# RL6678_IP_SVD register map
Vendor: Realtek
Registers are 32-bit, read-write, reset 0x0 unless marked. A register's access mark holds for its fields unless they carry their own. Offsets are from the block's base; [hi:lo] are bit positions; {n}, {i} and the like mark numbered series.

## MIPI_DSI_REG
Base 0x400EA000
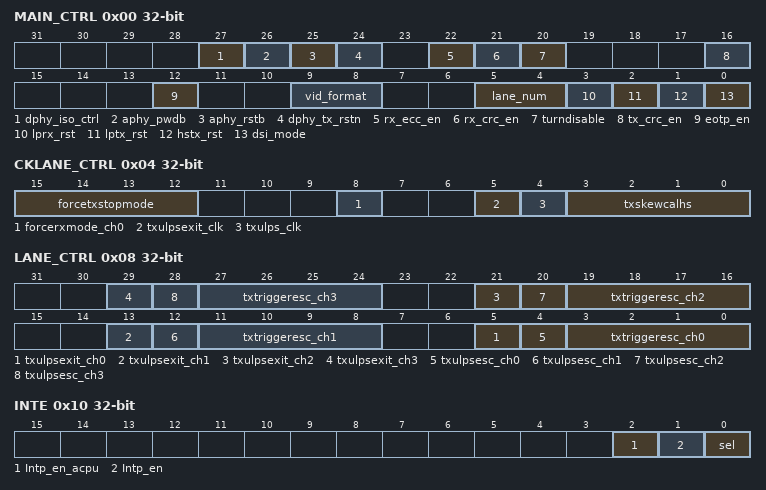
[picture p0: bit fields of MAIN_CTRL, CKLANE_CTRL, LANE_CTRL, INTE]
0x00 MAIN_CTRL
  [27] dphy_iso_ctrl — DPHY isolation function control 1: isolation mode 0: normal mode Related to DPHY port: BY_PASS_ON_MIPI
  [26] aphy_pwdb — APHY core power down signal for isolation
  [25] aphy_rstb — APHY reset signal
  [24] dphy_tx_rstn — DPHY external reset
  [22] rx_ecc_en — RX ECC check and correction enable
  [21] rx_crc_en — RX CRC check enable
  [20] turndisable — Disable Bus Turn Around (BTA) function.
  [16] tx_crc_en — TX CRC calculation enable
  [12] eotp_en — EOT packet enable
  [9:8] vid_format — Video stream data format 2'b00: 24bpp (8, 8, 8 RGB) 2'b01: 16bpp (5, 6, 5 RGB) 2'b10: 18bpp (6, 6, 6 RGB) packed 2'b11: 18bpp (6, 6, 6, RGB) loosely packed
  [5:4] lane_num — Lane number setting 2'b00: 1-lane 2'b01: 2-lane 2'b10: 3-lane 2'b11: 4-lane
  [3] lprx_rst — Async SW reset for LPRX function, set 1'b1 to reset LPRX function.
  [2] lptx_rst — Async SW reset for LPTX function, set 1'b1 to reset LPTX function.
  [1] hstx_rst — Async SW reset for HSTX function, set 1'b1 to reset HSTX function.
  [0] dsi_mode — DSI mode selection 0: command mode 1: video mode (shall be set after timing contrl register)
0x04 CKLANE_CTRL
  [15:12] forcetxstopmode — Force TX STOP
  [8] forcerxmode_ch0 — Force LPRX mode
  [5] txulpsexit_clk — Clock ULPS mode exit
  [4] txulps_clk — Clock ULPS mode enable
  [3:0] txskewcalhs — Skew Calibration
0x08 LANE_CTRL
  [8n+5] txulpsexit_ch{n} (n=0..3), [8n+4] txulpsesc_ch{n} (n=0..3), [8n+3:8n] txtriggeresc_ch{n} (n=0..3)
0x10 INTE
  [2] Intp_en_acpu — Set 1'b1 to enable DSI ACPU interrupt
  [1] Intp_en — Set 1'b1 to enable DSI SCPU interrupt
  [0] sel — Select which CPU to interrupt 0: SCPU 1: ACPU
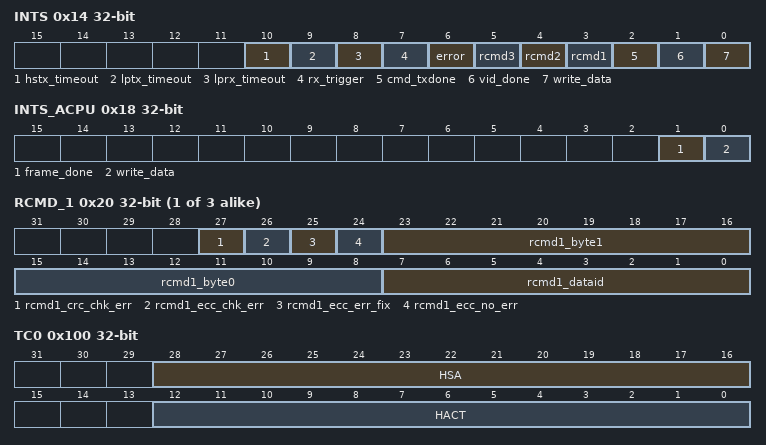
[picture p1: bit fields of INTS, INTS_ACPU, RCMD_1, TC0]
0x14 INTS access per field
  [10] hstx_timeout rw — HS Tx mode, timeout
  [9] lptx_timeout rw — LP Tx mode, timeout
  [8] lprx_timeout rw — LP Rx mode, timeout
  [7] rx_trigger rw — Received Rx trigger signal in DPHY_STATUS1
  [6] error rw — Error report in register DPHY_ERR
  [5] rcmd3 rw — Receive command mode response at RCMD3
  [4] rcmd2 rw — Receive command mode response at RCMD2
  [3] rcmd1 rw — Receive command mode response at RCMD1
  [2] cmd_txdone rw — Command mode Tx done
  [1] vid_done rw — Video mode frame Tx done
  [0] write_data wo
0x18 INTS_ACPU access per field
  [1] frame_done rw — Video mode frame done
  [0] write_data wo
{0x1C+4i} RCMD_{i} ro (i=1..3)
  [27] rcmd{i}_crc_chk_err — RCMD CRC check error
  [26] rcmd{i}_ecc_chk_err — RCMD ECC check error can't be fixed.
  [25] rcmd{i}_ecc_err_fix — RCMD ECC check error but fixed
  [24] rcmd{i}_ecc_no_err — RCMD ECC check error free
  [23:16] rcmd{i}_byte1 — Short command/long command header
  [15:8] rcmd{i}_byte0 — Short command/long command header
  [7:0] rcmd{i}_dataid — Short command/long command header
0x100 TC0
  [28:16] HSA — Set Hsync pulse width in bytes
  [12:0] HACT — Set video active width in bytes
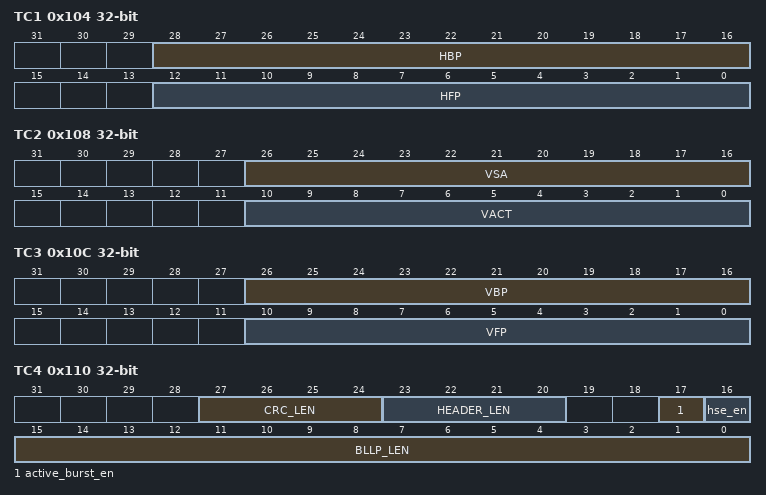
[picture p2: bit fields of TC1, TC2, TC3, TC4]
0x104 TC1
  [28:16] HBP — Set Horizontal Back Porch in bytes
  [12:0] HFP — Set Horizontal Front Porch in bytes
0x108 TC2
  [26:16] VSA — Set Vsync pulse width in Line
  [10:0] VACT — Set video active scan line numbers
0x10C TC3
  [26:16] VBP — Set Vertical Back Porch in Line
  [10:0] VFP — Set Vertical Front Porch in Line
0x110 TC4
  [27:24] CRC_LEN — Set HS mode CRC length in bytes
  [23:20] HEADER_LEN — Set HS mode Header length in bytes
  [17] active_burst_en — Send active data in burst mode (send EOTP in active lines)
  [16] hse_en — Enable register for Hsync end event packet
  [15:0] BLLP_LEN — Set clock request timing in byteclk cycles
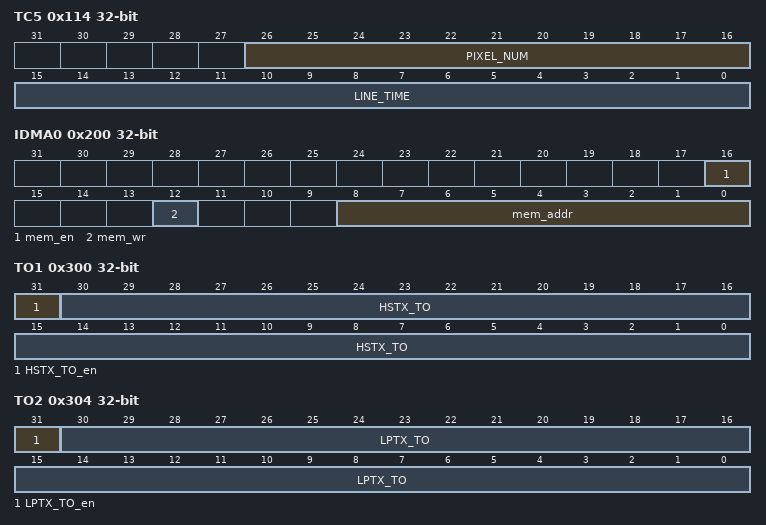
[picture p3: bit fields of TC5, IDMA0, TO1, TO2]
0x114 TC5
  [26:16] PIXEL_NUM — Set pixel numbers in pixel for VO PIF
  [15:0] LINE_TIME — Set HSTX line time in byteclk cycles
0x200 IDMA0
  [16] mem_en — In-direct memory access enable
  [12] mem_wr — 0: memory write 1: memory read
  [8:0] mem_addr — In-direct memory access
0x204 IDMA1
  [31:0] mem_d0 — Memory data bit[31:0]
0x208 IDMA2
  [31:0] mem_d1 — Memory data bit[63:32]
0x300 TO1
  [31] HSTX_TO_en — HSTX timout enable
  [30:0] HSTX_TO — HSTX timeout
0x304 TO2
  [31] LPTX_TO_en — LPTX timout enable
  [30:0] LPTX_TO — LPTX timeout
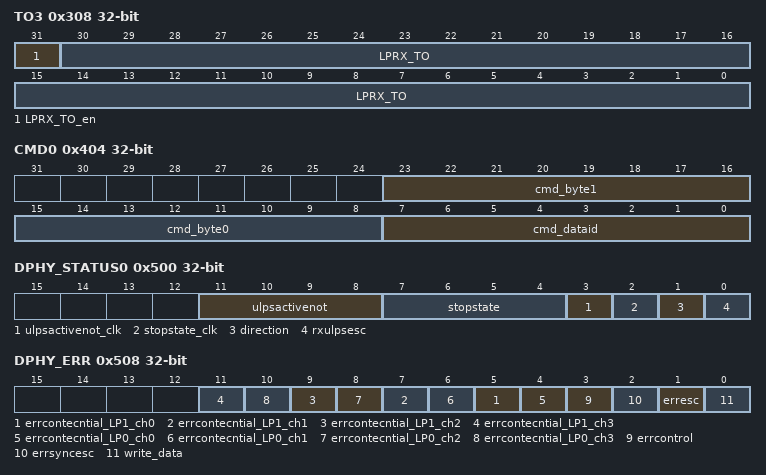
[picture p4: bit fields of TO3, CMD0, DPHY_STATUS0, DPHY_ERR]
0x308 TO3
  [31] LPRX_TO_en — LPRX timout enable
  [30:0] LPRX_TO — LPRX timeout
0x30C TO4
  [3:0] FIFO_RE_DLY — After FIFO_RE_DLY clock cycles delay, start to read FIFO to send HS data
0x400 CMD_GO
  [0] cmd_go — Set 1'b1 to start command transmission sequence
0x404 CMD0
  [23:16] cmd_byte1 — Short command/long command header direct write
  [15:8] cmd_byte0 — Short command/long command header direct write
  [7:0] cmd_dataid — Short command/long command header direct write
0x500 DPHY_STATUS0 ro
  [11:8] ulpsactivenot — Data lane ULPS mode indicator
  [7:4] stopstate — Data lane Stop State indicator
  [3] ulpsactivenot_clk — CLK lane ULPS mode indicator
  [2] stopstate_clk — CLK lane Stop State indicator
  [1] direction — Low Power Lane direction
  [0] rxulpsesc — RX ULPS mode indicator
0x504 DPHY_STATUS1 ro
  [3:0] rxtriggeresc — Escape mode trigger
0x508 DPHY_ERR access per field
  [2n+5] errcontecntial_LP1_ch{n} rw (n=0..3), [2n+4] errcontecntial_LP0_ch{n} rw (n=0..3), [3] errcontrol rw, [2] errsyncesc rw, [1] erresc rw, [0] write_data wo
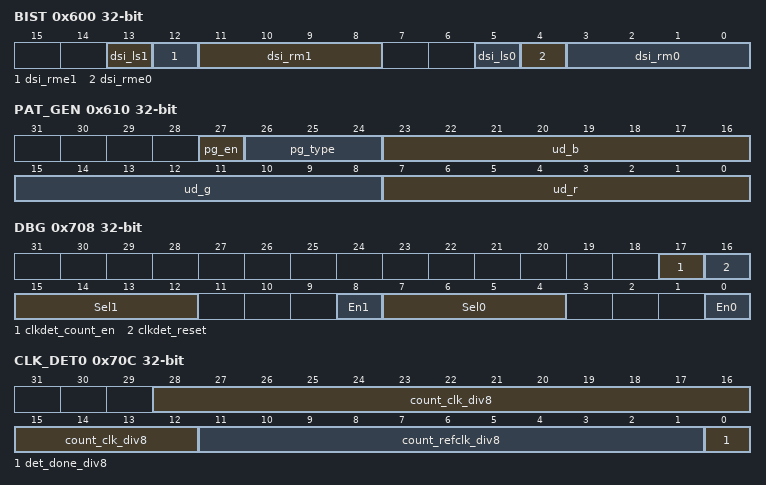
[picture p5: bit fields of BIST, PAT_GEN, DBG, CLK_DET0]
0x600 BIST
  [13] dsi_ls1 — LS control 1
  [12] dsi_rme1 — REM1
  [11:8] dsi_rm1 — RM1
  [5] dsi_ls0 — LS control 0
  [4] dsi_rme0 — REM0
  [3:0] dsi_rm0 — RM0
0x610 PAT_GEN
  [27] pg_en — Pattern generator enable
  [26:24] pg_type — 3'h0: color bar 3'h1: black 3'h2: white 3'h3: red 3'h4: blue 3'h5: yellow 3'h6: magenta 3'h7: user defined (ud_r, ud_g, ud_b)
  [23:16] ud_b — User-defined blue color space
  [15:8] ud_g — User-defined green color space
  [7:0] ud_r — User-defined red color space
0x700 DUMMY0
  [31:0] dummy_reg0 — Dummy register
0x704 DUMMY1
  [31:0] dummy_reg1 — Dummy register
0x708 DBG
  [17] clkdet_count_en — 1: start clock frequency detection
  [16] clkdet_reset — 0: reset crt_pll_div clk det function
  [15:12] Sel1 — Mux select for di_dbg_out1
  [8] En1 — Output enable for di_dbg_out1
  [7:4] Sel0 — Mux select for di_dbg_out0
  [0] En0 — Output enable for di_dbg_out0
0x70C CLK_DET0 ro
  [28:12] count_clk_div8 — Counter output
  [11:1] count_refclk_div8 — Counter output of ref clock
  [0] det_done_div8 — Clock detect done
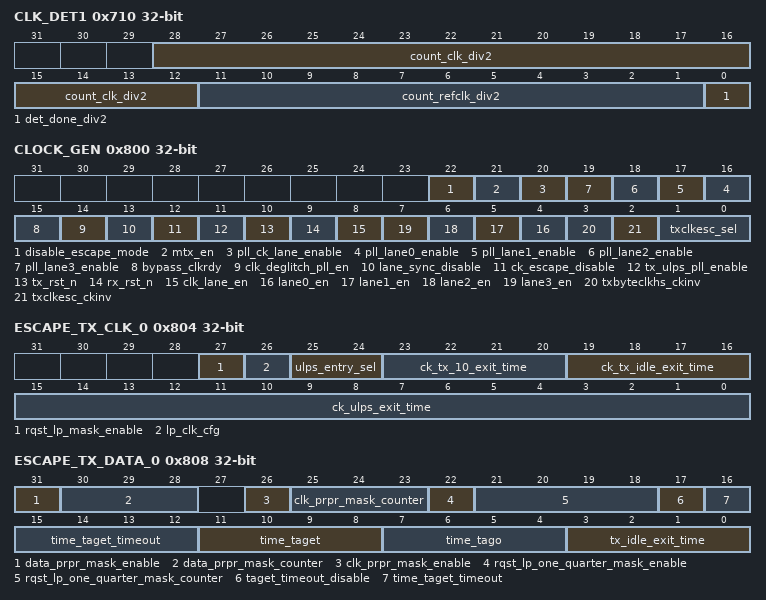
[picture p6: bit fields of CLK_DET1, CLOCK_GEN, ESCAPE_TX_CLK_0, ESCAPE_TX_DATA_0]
0x710 CLK_DET1 ro
  [28:12] count_clk_div2 — Counter output
  [11:1] count_refclk_div2 — Counter output of ref clock
  [0] det_done_div2 — Clock detect done
0x714 DBG_ST0 ro
  [31:0] dbg_pif — Debug status
0x718 DBG_ST1 ro
  [31:0] dbg_timegen — Debug status
0x71C DBG_ST2 ro
  [31:0] dbg_pktgen — Debug status
0x720 DBG_ST3 ro
  [31:0] dbg_ch_ctrl — Debug status
0x724 DBG_ST4 ro
  [31:0] dbg_cmd — Debug status
0x800 CLOCK_GEN
  [22] disable_escape_mode
  [21] mtx_en — Register for MTX_EN
  [20] pll_ck_lane_enable — Enable ulpsactivenot_ck_lane to control PLL enable
  [n+16] pll_lane{n}_enable (n=0..3) — Enable ulpsactivenot_ch{n} to control PLL enable
  [15] bypass_clkrdy — Clock gating bypass clkrdy
  [14] clk_deglitch_pll_en — PLL_EN clock deglitch 1'B1: Deglitch enable 1'B0: deglitch disable
  [13] lane_sync_disable — 4 lane sync disable
  [12] ck_escape_disable — Disable Tx Ctrl FSM TX_CK_RQST wait ck_escape_entry
  [11] tx_ulps_pll_enable — No use
  [10] tx_rst_n — Tx reset
  [9] rx_rst_n — Rx reset
  [8] clk_lane_en — LANE clock enable
  [n+4] lane{n}_en (n=0..3) — LANE{n} enable
  [3] txbyteclkhs_ckinv — TXBYTECLKHS INV 0: normal 1: INV
  [2] txclkesc_ckinv — TXCLKESC INV 0: normal 1: INV
  [1:0] txclkesc_sel — TXCLKESC SEL 00: TXCLKESC 01: TXBYTECLKHS 10: XTAL 11: XTAL
0x804 ESCAPE_TX_CLK_0
  [27] rqst_lp_mask_enable — Delete 0.5T T lp when Request
  [26] lp_clk_cfg — PN SWAP(connect to escape_tx_clk and tx_ctrl_l*) 1: SWAP 0: normal
  [25:24] ulps_entry_sel — 00: 01: need txrequest_clk is 0 10: need tx_ctrl FSM is TX_CK_STOP 11: need txrequest_clk is 0 && tx_ctrl FSM is TX_CK_STOP
  [23:20] ck_tx_10_exit_time — Timer: (FSM ck_tx_ulps_lp_10 ) CK lane LP10 timer
  [19:16] ck_tx_idle_exit_time — Timer: (FSM ck_tx_idle_lp_11) CK lane idle timer
  [15:0] ck_ulps_exit_time — Timer: (FSM ck_tx_ulps_lp_exit_10) unit is 800ns
0x808 ESCAPE_TX_DATA_0
  [31] data_prpr_mask_enable — Enable delete 0.125T clock prepare
  [30:28] data_prpr_mask_counter — 0: Delete 0.125*7 T 1: Delete 0.125*6 T 2: Delete 0.125*5 T 3: Delete 0.125*4 T 4: Delete 0.125*3 T 5: Delete 0.125*2 T 6: Delete 0.125*1 T 7: Delete 0.125*0 T
  [26] clk_prpr_mask_enable — Enable delete 0.125T clock prepare
  [25:23] clk_prpr_mask_counter — 0: Delete 0.125*7 T 1: Delete 0.125*6 T 2: Delete 0.125*5 T 3: Delete 0.125*4 T 4: Delete 0.125*3 T 5: Delete 0.125*2 T 6: Delete 0.125*1 T 7: Delete 0.125*0 T
  [22] rqst_lp_one_quarter_mask_enable — Delete 0.125T T lp when Request
  [21:18] rqst_lp_one_quarter_mask_counter — 0: Delete 0.125*1 T 1: Delete 0.125*2 T 2: Delete 0.125*3 T 3: Delete 0.125*4 T 4: Delete 0.125*5 T 5: Delete 0.125*6 T
  [17] taget_timeout_disable — Disable reg_taget_timeout_disable
  [16:12] time_taget_timeout — Timer: (FSM wait_RX_TA_ACK) TX2RX, wait slave sending ACK timer
  [11:8] time_taget — Timer: (FSM master_tx_state_00) T_ta_sure
  [7:4] time_tago — Timer:(FSM tx_arunaround_00_2) T_tago
  [3:0] tx_idle_exit_time — Timer:(FSM tx_idle_lp_11)
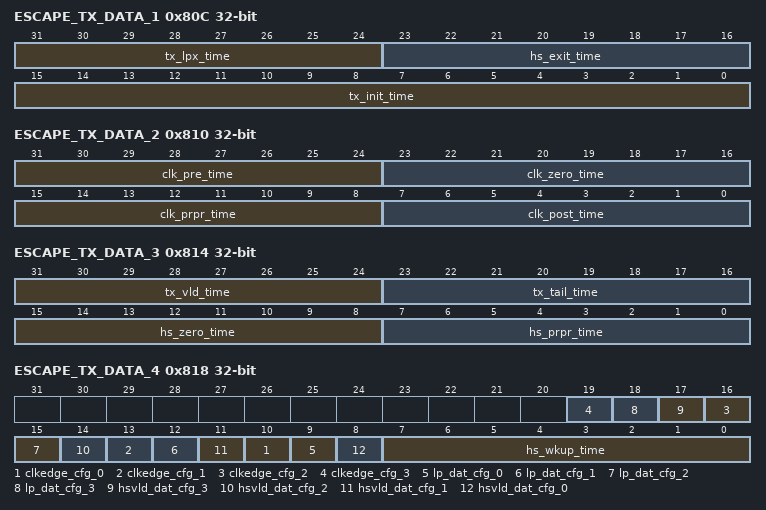
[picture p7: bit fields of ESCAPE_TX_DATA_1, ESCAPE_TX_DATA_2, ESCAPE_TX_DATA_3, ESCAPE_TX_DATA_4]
0x80C ESCAPE_TX_DATA_1
  [31:24] tx_lpx_time — Timer Clock period needs 48ns - 77ns (FSM TX_CK_RQST/TX_HS_RQST)
  [23:16] hs_exit_time — Timer (FSM TX_HS_STOP/TX_CK_STOP)
  [15:0] tx_init_time — Timer (FSM TX_INIT)
0x810 ESCAPE_TX_DATA_2
  [31:24] clk_pre_time — Timer (FSM TX_CK_PRE)
  [23:16] clk_zero_time — Timer (FSM TX_CK_ZERO)
  [15:8] clk_prpr_time — Timer (FSM TX_CK_PRPR)
  [7:0] clk_post_time — Timer (FSM TX_CK_POST)
0x814 ESCAPE_TX_DATA_3
  [31:24] tx_vld_time — Timer
  [23:16] tx_tail_time — Timer (FSM TX_CK_TRAIL/TX_HS_TRAIL)
  [15:8] hs_zero_time — Timer (FSM TX_HS_ZERO)
  [7:0] hs_prpr_time — Timer (FSM TX_HS_PRPR)
0x818 ESCAPE_TX_DATA_4
  [3n+10] clkedge_cfg_{n} (n=0..3) — Skew pattern (lane{n}) 1: 01010101 0: 10101010
  [3n+9] lp_dat_cfg_{n} (n=0..3) — PN SWAP (connect to escape_tx and tx_ctrl_l*) (lane{n}) 1: SWAP 0: normal
  [17] hsvld_dat_cfg_3 — TX_HS_DATA_VALID INV(connect to tx_ctrl_l*)(lane3) 1: INV 0: nornal
  [14] hsvld_dat_cfg_2 — TX_HS_DATA_VALID INV (connect to tx_ctrl_l*) (lane2) 1: INV 0: nornal
  [11] hsvld_dat_cfg_1 — TX_HS_DATA_VALID INV (connect to tx_ctrl_l*) (lane1) 1: INV 0: normal
  [8] hsvld_dat_cfg_0 — TX_HS_DATA_VALID INV (connect to tx_ctrl_l*) (lane0) 1: INV 0: nornal
  [7:0] hs_wkup_time — Timer
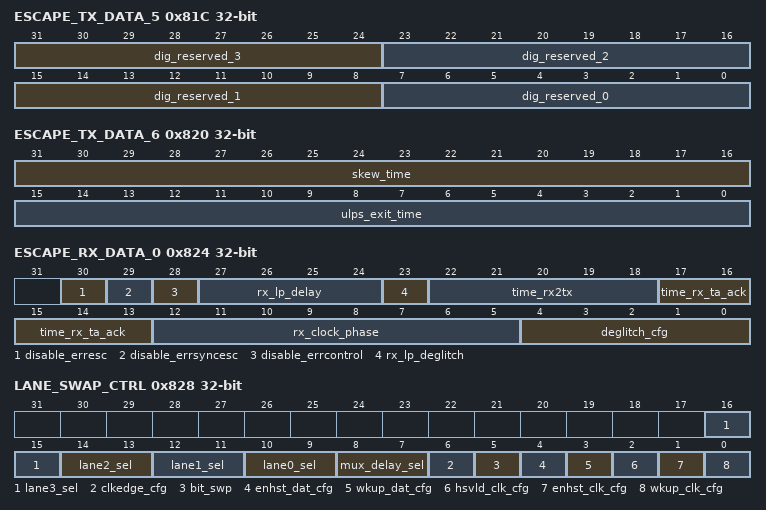
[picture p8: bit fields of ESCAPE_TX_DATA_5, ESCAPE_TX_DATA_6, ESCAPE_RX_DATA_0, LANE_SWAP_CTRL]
0x81C ESCAPE_TX_DATA_5
  [31:24] dig_reserved_3 — Digital reserved register
  [23:16] dig_reserved_2 — Digital reserved register
  [15:8] dig_reserved_1 — Bit[1]: reg_hswkp_data_advance 1: reg_hswkp_data raise early 1T 0: normal mode Bit[0]: reg_hswkp_cc_advance 1: reg_hswkp_cc raise early 1T 0: normal mode
  [7:0] dig_reserved_0 — Digital reserved register
0x820 ESCAPE_TX_DATA_6
  [31:16] skew_time — Skew timer: the minimum time for HS burst
  [15:0] ulps_exit_time — Timer, unit is 50 ns (FSM tx_ulps_exit_10)
0x824 ESCAPE_RX_DATA_0
  [30] disable_erresc
  [29] disable_errsyncesc
  [28] disable_errcontrol
  [27:24] rx_lp_delay — Rx low power signal TX2RX delay
  [23] rx_lp_deglitch — Deglitch
  [22:18] time_rx2tx — Timer Extend signal RX2TX FSM from master_rx_state to master_tx_state_00
  [17:13] time_rx_ta_ack — Timer Extend signal rx_ta_ack FSM from wait_RX_TA_ACK to master_rx_state
  [12:5] rx_clock_phase — Rx clock phase [7:6]: lane3 [5:4]: lane2 [3:2]: lane1 [1:0]: lane0 2'B11: 4T 2'B10: 3T 2'B01: 2T 2'B00: 1T
  [4:0] deglitch_cfg — Rx stop state deglitch [4]: lane ck [3]: lane3 [2]: lane2 [1]: lane1 [0]: lane0
0x828 LANE_SWAP_CTRL
  [2n+10:2n+9] lane{n}_sel (n=0..3) — Lane swap select
  [8:7] mux_delay_sel — Tx_ctrl/tx escape select signal 2'b11: sync 3T 2'b10: sync 2T 2'b01: sync 1T 2'b00: sync 0T
  [6] clkedge_cfg — CK lane HS data 1: 01010101 0: 10101010
  [5] bit_swp — 1: SWAP 0: normal
  [4] enhst_dat_cfg — 1: INV 0: normal
  [3] wkup_dat_cfg — 1: INV 0: normal
  [2] hsvld_clk_cfg — 1: INV 0: normal
  [1] enhst_clk_cfg — 1: INV 0: normal
  [0] wkup_clk_cfg — 1: INV 0: normal
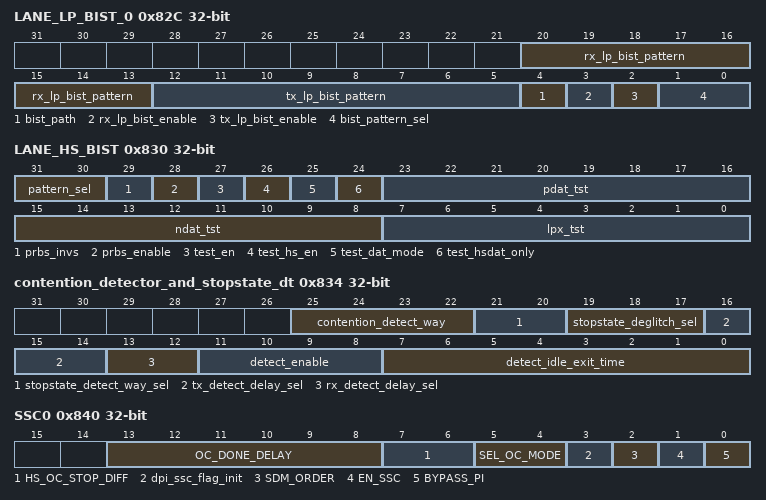
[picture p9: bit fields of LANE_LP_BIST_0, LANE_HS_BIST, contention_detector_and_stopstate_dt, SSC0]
0x82C LANE_LP_BIST_0
  [20:13] rx_lp_bist_pattern
  [12:5] tx_lp_bist_pattern
  [4] bist_path — Select BIST path
  [3] rx_lp_bist_enable — BIST Rx enable
  [2] tx_lp_bist_enable — BIST Tx enable
  [1:0] bist_pattern_sel — 2'b11: cnt 2'b10: reg_tx_lp_bist_pattern 2'b01: 8'b1100_1100 2'b00: 8'b0101_1010
0x830 LANE_HS_BIST
  [31:30] pattern_sel — Pattern sel 2'b11: PRBS 23 2'b10: PRBS7 2'b01: CRC32 2'b00: from pdat and ndat
  [29] prbs_invs — PRBS inverse
  [28] prbs_enable
  [27] test_en — Enable
  [26] test_hs_en — HS enable
  [25] test_dat_mode — No use
  [24] test_hsdat_only — Test pattern select
  [23:16] pdat_tst — Manual data
  [15:8] ndat_tst — Manual data
  [7:0] lpx_tst — LP length counter
0x834 contention_detector_and_stopstate_dt
  [25:22] contention_detect_way — Contention detect way reg_contention_detect_way [1]: 1: LP0 use LDPC_H 0: LP0 use LDPC_L reg_contention_detect_way [0]: 1: LP1 use LDPC_H 0: LP1 use LDPC_L
  [21:20] stopstate_detect_way_sel
  [19:17] stopstate_deglitch_sel
  [16:14] tx_detect_delay_sel — Tx delay sel
  [13:12] rx_detect_delay_sel — Rx delay sel
  [11:8] detect_enable — [0]: LP0_dp [1]: LP0_dm [2]: LP1_dp [3]: LP1_dm
  [7:0] detect_idle_exit_time — Contention detect idle exit time
0x838 DEBUG_0
  [7:0] dig_debug_sel — Debug address
0x83C DEBUG_1 ro
  [29:0] debug_out — DEBUG_OUT signal
0x840 SSC0
  [13:8] OC_DONE_DELAY — Delay to setting OC_DONE=b1 after over-clock or under-clock is done by (REG_OC_DONE_delay*Tref)
  [7:6] HS_OC_STOP_DIFF — HS stop control b00: HS OC stop at (Target_freq-2*fref) b01: HS OC stop at (Target_freq-6*fref) b10: HS OC stop at (Target_freq-10*fref) b11: HS OC stop at (Target_freq-14*fref)
  [5:4] SEL_OC_MODE — Over-clock/Under-clock mode selection b00: Low speed mode b01: High speed mode b10: Adaptive high speed mode
  [3] dpi_ssc_flag_init — SSC initial flag
  [2] SDM_ORDER — Select 1st-order or 2nd-order SDM
  [1] EN_SSC — Enable SSC function 1: Enable 0: Disable
  [0] BYPASS_PI — When no fractional divider or SSC, bypass Phase Interpolator for CMU loop 0: including PI inside the loop 1: bypass PI inside the loop
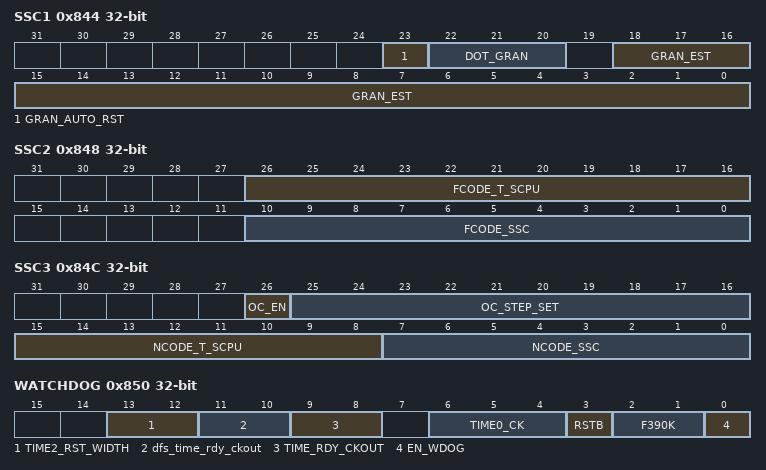
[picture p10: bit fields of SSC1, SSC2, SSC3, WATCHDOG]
0x844 SSC1
  [23] GRAN_AUTO_RST — When FMOD transition, reset SDM
  [22:20] DOT_GRAN — Decimal point position of GRAN b000: 4.15 b001: 5.14 b010: 6.13 b011: 7.12 b100: 8.11
  [18:0] GRAN_EST — SSC step SSC step=(Fssc-F) / (0.5*Tssc)
0x848 SSC2
  [26:16] FCODE_T_SCPU — Fractional code of loop divider (target Fcode of overclocking)
  [10:0] FCODE_SSC — Fractional code of loop divider
0x84C SSC3
  [26] OC_EN — Enable over-clock or under-clock
  [25:16] OC_STEP_SET — Over-clock / Under-clock slope control of low speed mode
  [15:8] NCODE_T_SCPU — Integer code of loop divider,real divider code is (target Ncode of overclocking) CKREF=27M, REG_PDIV=b00, REG_BYPASS_PI=b0, VCO frequency=27*( REG_N_CODE [7:0] +3+ REG_F_CODE<10:0>/2048)=1.6GHz -> REG_N_CODE [7:0] =56, REG_F_CODE<10:0>=531
  [7:0] NCODE_SSC — Integer code of loop divider,real divider code is CKREF=27M, REG_PDIV=b00, REG_BYPASS_PI=b0, VCO frequency=27*( REG_N_CODE [7:0] +3+ REG_F_CODE<10:0>/2048)=1.0GHz -> REG_N_CODE [7:0] =34, REG_F_CODE<10:0>=76
0x850 WATCHDOG
  [13:12] TIME2_RST_WIDTH — Reset timing control (REG_TIME_RST_WIDTH x CKREF) d0: 2 d1: 4 d2: 8 d3: 20
  [11:10] dfs_time_rdy_ckout — DFS Clock ready timing control (clock ready time: 2 times the value of REG_TIME_WD x CKREF + REG_TIME_RDY_CKOUT x CKTXPLL) d0: 3 d1: 100 d2: 200 d3: 600
  [9:8] TIME_RDY_CKOUT — Clock ready timing control (clock ready time: 2 times the value of REG_TIME_WD x CKREF + REG_TIME_RDY_CKOUT x CKTXPLL) d0: 3 d1: 100 d2: 200 d3: 600
  [6:4] TIME0_CK — Watchdog timing control (clock output time: 2 times the value of REG_TIME_WD x CKREF) d0: 2 d1: 200 d2: 600 d3: 1200 d4: 3000 d5: 6400 d6: 12800 d7: 16000
  [3] RSTB — Reset SDM
  [2:1] F390K — F390K output delay, not used
  [0] EN_WDOG — Enable watch dog function 0: disable Watch Dog function 1: enable Watch Dog function
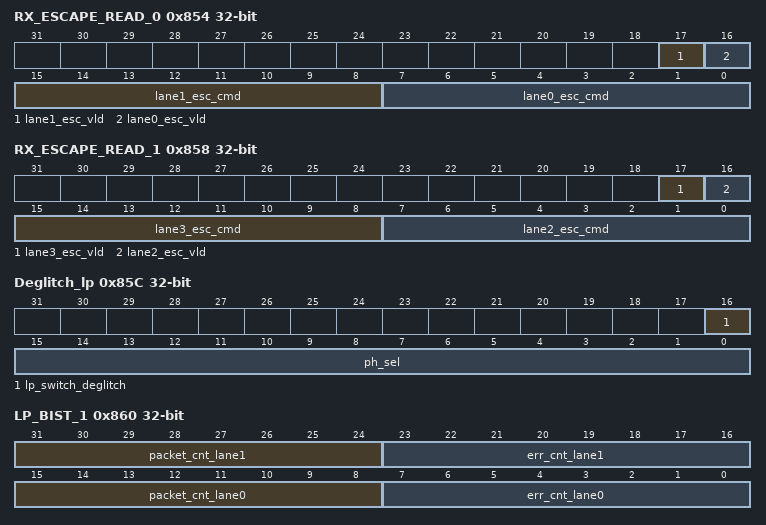
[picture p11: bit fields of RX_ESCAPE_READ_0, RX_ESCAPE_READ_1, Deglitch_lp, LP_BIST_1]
0x854 RX_ESCAPE_READ_0 ro
  [17] lane1_esc_vld — Esc command valid
  [16] lane0_esc_vld — Esc command valid
  [15:8] lane1_esc_cmd — Esc command
  [7:0] lane0_esc_cmd — Esc command
0x858 RX_ESCAPE_READ_1 ro
  [17] lane3_esc_vld — Esc command valid
  [16] lane2_esc_vld — Esc command valid
  [15:8] lane3_esc_cmd — Esc command
  [7:0] lane2_esc_cmd — Esc command
0x85C Deglitch_lp
  [16] lp_switch_deglitch — LP deglitch enable
  [15:0] ph_sel — Delay chain phase select
0x860 LP_BIST_1 ro
  [31:24] packet_cnt_lane1 — Packet counter lane1
  [23:16] err_cnt_lane1 — Error counter lane1
  [15:8] packet_cnt_lane0 — Packet counter lane0
  [7:0] err_cnt_lane0 — Error counter lane0
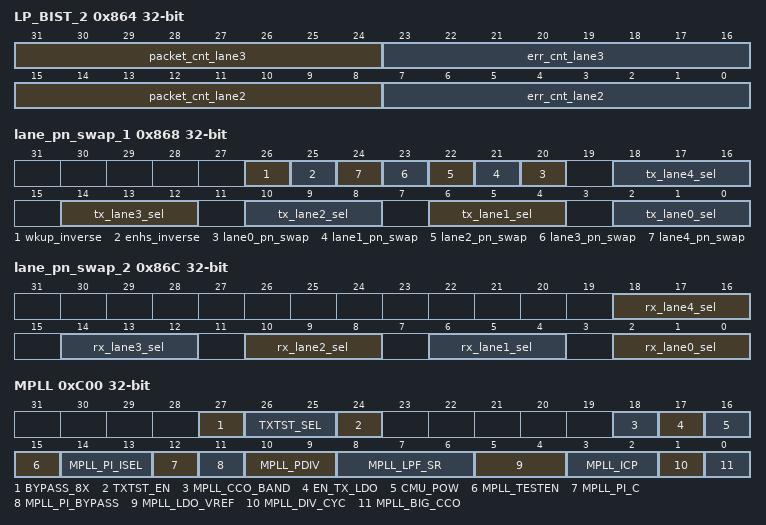
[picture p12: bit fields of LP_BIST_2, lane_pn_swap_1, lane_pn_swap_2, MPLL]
0x864 LP_BIST_2 ro
  [31:24] packet_cnt_lane3 — Packet counter lane3
  [23:16] err_cnt_lane3 — Error counter lane3
  [15:8] packet_cnt_lane2 — Packet counter lane2
  [7:0] err_cnt_lane2 — Error counter lane2
0x868 lane_pn_swap_1
  [26] wkup_inverse — HS wakeup signal inverse
  [25] enhs_inverse — HS enhs signal inverse
  [n+20] lane{n}_pn_swap (n=0..4) — PN swap in digital lane {n}
  [4n+2:4n] tx_lane{n}_sel (n=0..4) — Tx Lane swap select If digital lane 4 connects to analog lane {n}, reg_tx_lane{n}_sel needs to set to 3'd4
0x86C lane_pn_swap_2
  [4n+2:4n] rx_lane{n}_sel (n=0..4) — Rx Lane swap select If digital lane {n} connects to analog lane 4, reg_rx_lane{n}_sel needs to set to 3'd4
0xC00 MPLL
  [27] BYPASS_8X — CLK1X_DIG select signal, replace TXPLL ouput
  [26:25] TXTST_SEL — P2S debug output select
  [24] TXTST_EN — P2S debug enable
  [18] MPLL_CCO_BAND — Tx PLL
  [17] EN_TX_LDO — 1.2v TXLA LDO enalbe
  [16] CMU_POW — TXPLL enable signal
  [15] MPLL_TESTEN — TXPLL's debug enable
  [14:13] MPLL_PI_ISEL — TXPLL's PI bias current config
  [12] MPLL_PI_C — TXPLL's PI Cap config
  [11] MPLL_PI_BYPASS — TXPLL's PI output bypass signal
  [10:9] MPLL_PDIV — TXPLL's pre dividre control
  [8:6] MPLL_LPF_SR — TXPLL's LPF R control
  [5:4] MPLL_LDO_VREF — TXPLL's LDO reference control
  [3:2] MPLL_ICP — TXPLL's charge pump control
  [1] MPLL_DIV_CYC — TXPLL's loop divider pulse width control
  [0] MPLL_BIG_CCO — TXPLL KVCO selection
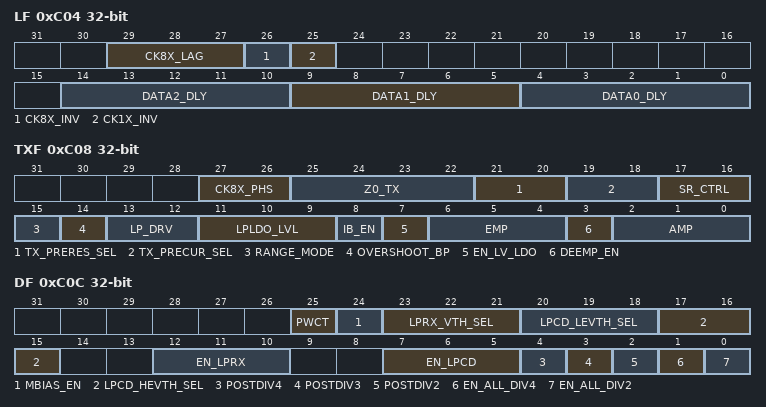
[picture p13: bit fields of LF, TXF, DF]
0xC04 LF
  [29:27] CK8X_LAG — CK8X lag config
  [26] CK8X_INV — CK8X inverser config
  [25] CK1X_INV — CK1X inverse config
  [14:10] DATA2_DLY — DATA2 lane's skew delay control
  [9:5] DATA1_DLY — DATA1 lane's skew delay control
  [4:0] DATA0_DLY — DATA0 lane's skew delay control
0xC08 TXF
  [27:26] CK8X_PHS — CK8X phase select, not used here
  [25:22] Z0_TX — TXLA's term reset control
  [21:20] TX_PRERES_SEL — TXLA's pre amp reload control
  [19:18] TX_PRECUR_SEL — TXLA's pre amp current control
  [17:16] SR_CTRL — Tx PAD GPIO mode slew rate control
  [15] RANGE_MODE — TXLA's LDO output level config
  [14] OVERSHOOT_BP — TXLA's overshoot bypass
  [13:12] LP_DRV — LP mode Tx slew rate control
  [11:9] LPLDO_LVL — TXLA's LDO output level config
  [8] IB_EN — HS CML bias current enable
  [7] EN_LV_LDO — 1.5v TXPLL LDO enalbe
  [6:4] EMP — HS CML driver deemphasis swing config
  [3] DEEMP_EN — HS CML driver deemphasis enalbe signal
  [2:0] AMP — HS CML driver output swing config
0xC0C DF
  [25] PWCT — Analog power switch enable
  [24] MBIAS_EN — PLL post divider, all div4 selection
  [23:21] LPRX_VTH_SEL — PLL post divider, all div4 selection
  [20:18] LPCD_LEVTH_SEL — PLL post divider, all div4 selection
  [17:15] LPCD_HEVTH_SEL — PLL post divider, all div4 selection
  [12:10] EN_LPRX
  [7:5] EN_LPCD
  [4] POSTDIV4 — PLL post divider, all div4 selection
  [3] POSTDIV3 — PLL post divider, all div4 selection
  [2] POSTDIV2 — PLL post divider, all div4 selection
  [1] EN_ALL_DIV4 — PLL post divider, all div4 selection
  [0] EN_ALL_DIV2 — PLL post divider, all div2 selection
